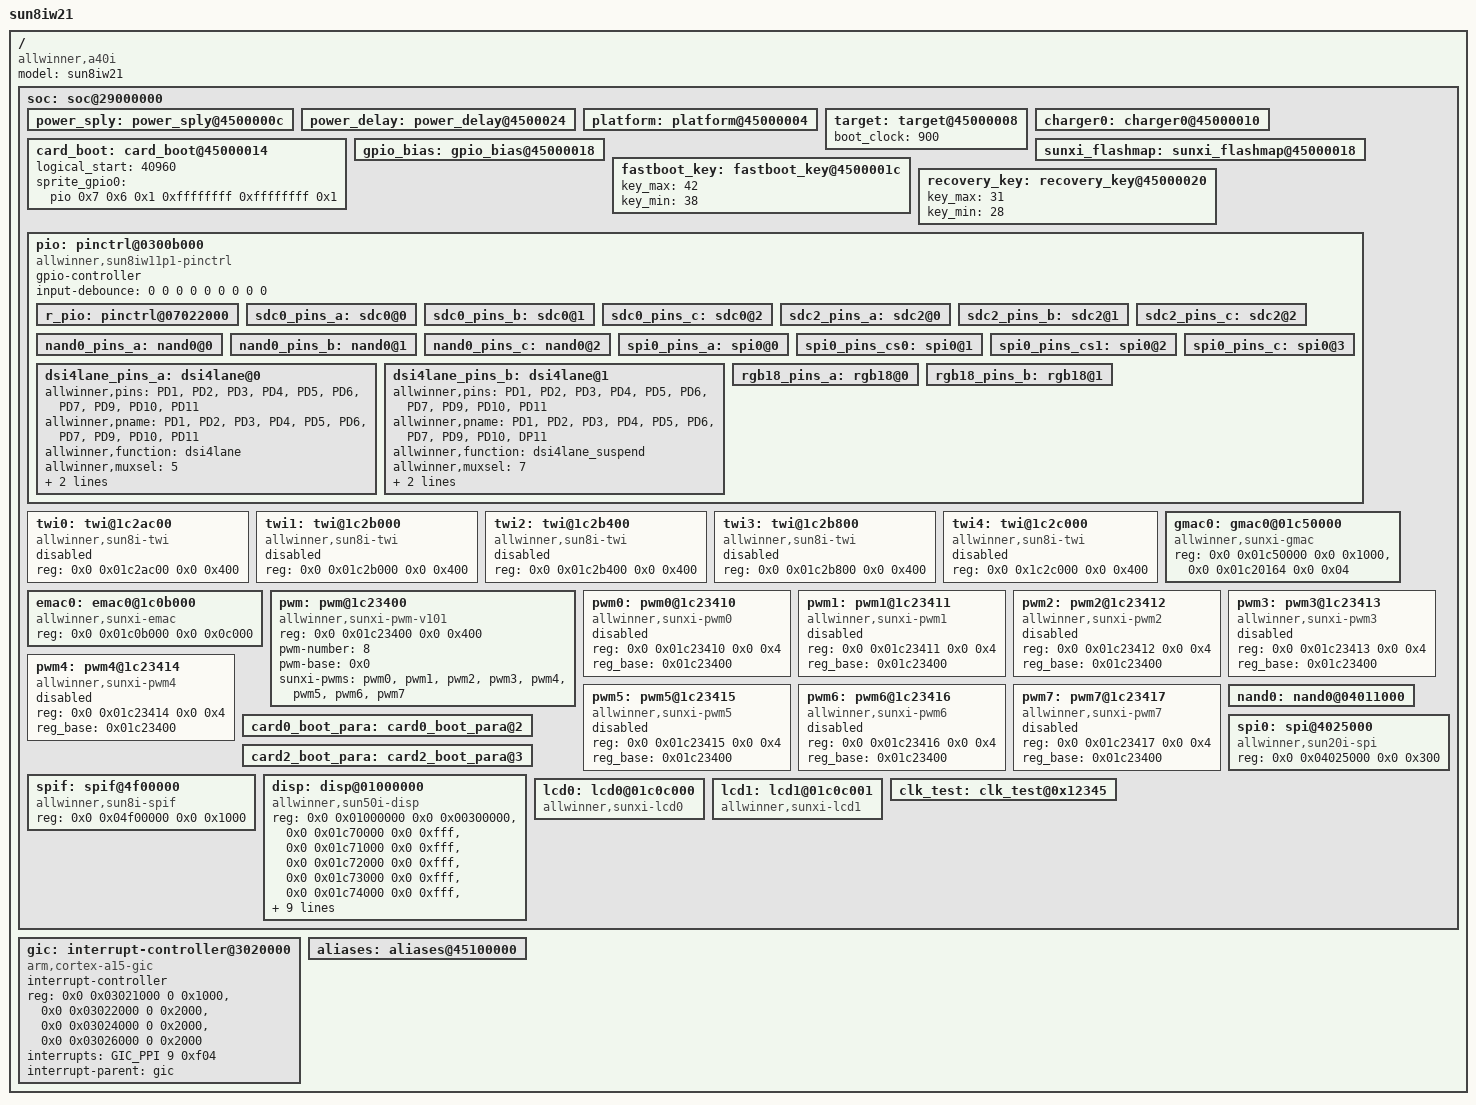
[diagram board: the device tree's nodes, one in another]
/*
 * Allwinner Technology CO., Ltd. sun8iw21p1 platform
 *
 * modify base on juno.dts
 */
/dts-v1/;
#include <dt-bindings/interrupt-controller/arm-gic.h>
#include <dt-bindings/gpio/gpio.h>
#include "sun8iw11p1-clk.dtsi"
/*#include "sun8iw21p1-pinctrl.dtsi"*/
#include <dt-bindings/thermal/thermal.h>
/ {
	model = "sun8iw21";
	compatible = "allwinner,a40i", "arm,sun8iw11p1";
	#address-cells = <2>;
	#size-cells = <2>;
	soc: soc@29000000 {
		#address-cells = <2>;
		#size-cells = <2>;
		device_type = "soc";
		power_sply:power_sply@4500000c {
			device_type = "power_sply";

		};

		power_delay:power_delay@4500024 {
			device_type = "power_delay";
		};

		platform:platform@45000004 {
			device_type = "platform";

		};

		target:target@45000008 {
			device_type = "target";
			boot_clock = <900>;

		};

		charger0:charger0@45000010 {
			device_type = "charger0";

		};
		card_boot:card_boot@45000014 {
			device_type = "card_boot";
			logical_start   = <40960>;
			/* sprite_gpio0 = <&pio PH 6 1 0xffffffff 0xffffffff 1>; */
			sprite_gpio0 = <&pio 0x7 0x6 0x1 0xffffffff 0xffffffff 0x1>;
		};

		gpio_bias:gpio_bias@45000018 {
			device_type = "gpio_bias";
		};

		sunxi_flashmap:sunxi_flashmap@45000018 {
			device_type = "sunxi_flashmap";
		};

		fastboot_key:fastboot_key@4500001c {
			device_type = "fastboot_key";
			key_max = <42>;
			key_min = <38>;
		};

		recovery_key:recovery_key@45000020 {
			device_type = "recovery_key";
			key_max = <31>;
			key_min = <28>;
		};

		pio: pinctrl@0300b000 {
			compatible = "allwinner,sun8iw11p1-pinctrl";
			device_type = "pio";
			gpio-controller;
			#size-cells = <0>;
			#gpio-cells = <6>;
			/* takes the debounce time in usec as argument */
			input-debounce = <0 0 0 0 0 0 0 0 0>;
			r_pio: pinctrl@07022000 {
			};
			sdc0_pins_a: sdc0@0 {
			};

			sdc0_pins_b: sdc0@1 {
			};

			sdc0_pins_c: sdc0@2 {
			};

			sdc2_pins_a: sdc2@0 {
			};

			sdc2_pins_b: sdc2@1 {
			};

			sdc2_pins_c: sdc2@2 {
			};

			nand0_pins_a: nand0@0 {
			};

			nand0_pins_b: nand0@1 {
			};

			nand0_pins_c: nand0@2 {
			};

			spi0_pins_a: spi0@0 {
			};

			spi0_pins_cs0: spi0@1 {
			};

			spi0_pins_cs1: spi0@2 {
			};

			spi0_pins_c: spi0@3 {
			};

			dsi4lane_pins_a: dsi4lane@0 {
				allwinner,pins = "PD1", "PD2", "PD3", "PD4", "PD5", "PD6", "PD7", "PD9", "PD10", "PD11";
				allwinner,pname = "PD1", "PD2", "PD3", "PD4", "PD5", "PD6", "PD7", "PD9", "PD10", "PD11";
				allwinner,function = "dsi4lane";
				allwinner,muxsel = <5>;
				allwinner,drive = <3>;
				allwinner,pull = <0>;
			};

			dsi4lane_pins_b: dsi4lane@1 {
				allwinner,pins = "PD1", "PD2", "PD3", "PD4", "PD5", "PD6", "PD7", "PD9", "PD10", "PD11";
				allwinner,pname = "PD1", "PD2", "PD3", "PD4", "PD5", "PD6", "PD7", "PD9", "PD10", "DP11";
				allwinner,function = "dsi4lane_suspend";
				allwinner,muxsel = <7>;
				allwinner,drive = <1>;
				allwinner,pull = <0>;
			};

			rgb18_pins_a: rgb18@0 {
			};
			rgb18_pins_b: rgb18@1 {
			};
		};

		twi0: twi@1c2ac00 {
			#address-cells = <1>;
			#size-cells = <0>;
			compatible = "allwinner,sun8i-twi";
			device_type = "twi0";
			reg = <0x0 0x01c2ac00 0x0 0x400>;
			status = "disabled";
		};

		twi1: twi@1c2b000 {
			#address-cells = <1>;
			#size-cells = <0>;
			compatible = "allwinner,sun8i-twi";
			device_type = "twi1";
			reg = <0x0 0x01c2b000 0x0 0x400>;
			status = "disabled";
		};

		twi2: twi@1c2b400 {
			#address-cells = <1>;
			#size-cells = <0>;
			compatible = "allwinner,sun8i-twi";
			device_type = "twi2";
			reg = <0x0 0x01c2b400 0x0 0x400>;
			status = "disabled";
		};

		twi3: twi@1c2b800 {
			#address-cells = <1>;
			#size-cells = <0>;
			compatible = "allwinner,sun8i-twi";
			device_type = "twi3";
			reg = <0x0 0x01c2b800 0x0 0x400>;
			status = "disabled";
		};

		twi4: twi@1c2c000 {
			#address-cells = <1>;
			#size-cells = <0>;
			compatible = "allwinner,sun8i-twi";
			device_type = "twi4";
			reg = <0x0 0x1c2c000 0x0 0x400>;
			status = "disabled";
		};

		gmac0: gmac0@01c50000 {
			compatible = "allwinner,sunxi-gmac";
			reg = <0x0 0x01c50000 0x0 0x1000>,
			    <0x0 0x01c20164 0x0 0x04>;
			status = "okay";
		};

		emac0: emac0@1c0b000 {
			compatible = "allwinner,sunxi-emac";
			reg = <0x0 0x01c0b000 0x0 0x0c000>;
			status = "okay";
		};

		pwm: pwm@1c23400 {
			#pwm-cells = <0x3>;
			compatible = "allwinner,sunxi-pwm-v101";
			reg = <0x0 0x01c23400 0x0 0x400>;
			pwm-number = <8>;
			pwm-base = <0x0>;
			sunxi-pwms = <&pwm0>, <&pwm1>, <&pwm2>, <&pwm3>, <&pwm4>, <&pwm5>, <&pwm6>, <&pwm7>;
		};

		pwm0: pwm0@1c23410 {
			#pwm-cells = <0x3>;
			compatible = "allwinner,sunxi-pwm0";
			reg = <0x0 0x01c23410 0x0 0x4>;
			reg_base = <0x01c23400>;
			status = "disabled";
		};

		pwm1: pwm1@1c23411 {
			#pwm-cells = <0x3>;
			compatible = "allwinner,sunxi-pwm1";
			reg = <0x0 0x01c23411 0x0 0x4>;
			reg_base = <0x01c23400>;
			status = "disabled";
		};

		pwm2: pwm2@1c23412 {
			#pwm-cells = <0x3>;
			compatible = "allwinner,sunxi-pwm2";
			reg = <0x0 0x01c23412 0x0 0x4>;
			reg_base = <0x01c23400>;
			status = "disabled";
		};

		pwm3: pwm3@1c23413 {
			#pwm-cells = <0x3>;
			compatible = "allwinner,sunxi-pwm3";
			reg = <0x0 0x01c23413 0x0 0x4>;
			reg_base = <0x01c23400>;
			status = "disabled";
		};

		pwm4: pwm4@1c23414 {
			#pwm-cells = <0x3>;
			compatible = "allwinner,sunxi-pwm4";
			reg = <0x0 0x01c23414 0x0 0x4>;
			reg_base = <0x01c23400>;
			status = "disabled";
		};

		pwm5: pwm5@1c23415 {
			#pwm-cells = <0x3>;
			compatible = "allwinner,sunxi-pwm5";
			reg = <0x0 0x01c23415 0x0 0x4>;
			reg_base = <0x01c23400>;
			status = "disabled";
		};

		pwm6: pwm6@1c23416 {
			#pwm-cells = <0x3>;
			compatible = "allwinner,sunxi-pwm6";
			reg = <0x0 0x01c23416 0x0 0x4>;
			reg_base = <0x01c23400>;
			status = "disabled";
		};

		pwm7: pwm7@1c23417 {
			#pwm-cells = <0x3>;
			compatible = "allwinner,sunxi-pwm7";
			reg = <0x0 0x01c23417 0x0 0x4>;
			reg_base = <0x01c23400>;
			status = "disabled";
		};

		card0_boot_para:card0_boot_para@2 {
			device_type = "card0_boot_para";
		};

		card2_boot_para:card2_boot_para@3 {
			device_type = "card2_boot_para";
		};

		nand0:nand0@04011000 {
			device_type = "nand0";
		};

		spi0: spi@4025000 {
			#address-cells = <1>;
			#size-cells = <0>;
			compatible = "allwinner,sun20i-spi";
			device_type = "spi0";
			reg = <0x0 0x04025000 0x0 0x300>;
			//interrupts-extended = <&plic0 31 IRQ_TYPE_LEVEL_HIGH>;
			//clocks = <&ccu CLK_PLL_PERIPH0>, <&ccu CLK_SPI0>, <&ccu CLK_BUS_SPI0>;
			//clock-names = "pll", "mod", "bus";
			//resets = <&ccu RST_BUS_SPI0>;
		};

		spif: spif@4f00000 {
			#address-cells = <1>;
			#size-cells = <0>;
			compatible = "allwinner,sun8i-spif";
			device_type = "spif";
			reg = <0x0 0x04f00000 0x0 0x1000>;
			//interrupts-extended = <&plic0 19 IRQ_TYPE_LEVEL_HIGH>;
			//clocks = <&ccu CLK_PLL_PERIPH0>, <&ccu CLK_SPIF>, <&ccu CLK_BUS_SPIF>;
			//clock-names = "pll", "mod", "bus";
			//resets = <&ccu RST_BUS_SPIF>;
		};

		disp: disp@01000000 {
			compatible = "allwinner,sun50i-disp";
			reg = <0x0 0x01000000 0x0 0x00300000>,/*de*/
				<0x0 0x01c70000 0x0 0xfff>,/*tcon top*/
				<0x0 0x01c71000 0x0 0xfff>,/*tcon0*/
				<0x0 0x01c72000 0x0 0xfff>,/*tcon1*/
				<0x0 0x01c73000 0x0 0xfff>,/*tcon2*/
				<0x0 0x01c74000 0x0 0xfff>,/*tcon3*/
				<0x0 0x01ca0000 0x0 0x10fc>;/*dsi*/
			interrupts = <GIC_SPI 44 0x0104>, <GIC_SPI 45 0x0104>,
				<GIC_SPI 51 0x0104>, <GIC_SPI 52 0x0104>,
				<GIC_SPI 57 0x0104>;/* for dsi */
			clocks = <&clk_de>,<&clk_tcon_top>,
						<&clk_tcon0>,<&clk_tcon1>,
						<&clk_tcon_tv0>,<&clk_tcon_tv1>,<&clk_lvds>,<&clk_mipidsi>;
			boot_disp = <0>;
			fb_base = <0>;

			status = "okay";
		};

		lcd0: lcd0@01c0c000 {
			compatible = "allwinner,sunxi-lcd0";
			pinctrl-names = "active","sleep";

			status = "okay";
		};
		lcd1: lcd1@01c0c001 {
			compatible = "allwinner,sunxi-lcd1";
			pinctrl-names = "active","sleep";

			status = "okay";
		};

		clk_test: clk_test@0x12345 {
			// clocks = <&clk_de>,
			// 	 <&clk_dpss_top>,
			// 	 <&clk_tcon_lcd>,
			// 	 <&clk_mipi_dsi>;
			status = "okay";
		};
	};

	gic: interrupt-controller@3020000 {
		compatible = "arm,cortex-a15-gic", "arm,cortex-a9-gic";
		#interrupt-cells = <3>;
		#address-cells = <0>;
		device_type = "gic";
		interrupt-controller;
		reg = <0x0 0x03021000 0 0x1000>, /* GIC Dist */
			<0x0 0x03022000 0 0x2000>, /* GIC CPU */
			<0x0 0x03024000 0 0x2000>, /* GIC VCPU Control */
			<0x0 0x03026000 0 0x2000>; /* GIC VCPU */
		interrupts = <GIC_PPI 9 0xf04>;  /* GIC Maintenence IRQ */
		interrupt-parent = <&gic>;
	};
	aliases:aliases@45100000 {
	};

};

#include ".board-uboot.dts"
